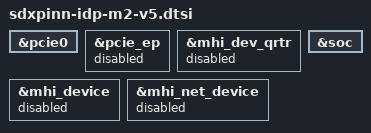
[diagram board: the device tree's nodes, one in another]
&pcie0 {
	status = "ok";
};

&pcie_ep {
	status = "disabled";
};

&mhi_dev_qrtr {
	status = "disabled";
};

&mhi_device {
	status = "disabled";
};

&mhi_net_device {
	status = "disabled";
};

&soc {
};
